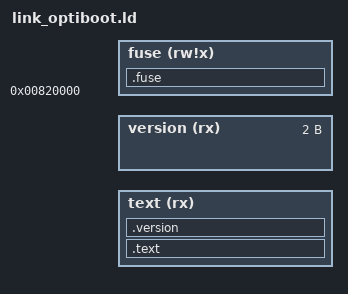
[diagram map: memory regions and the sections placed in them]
/* Customized Linker script for Optiboot */

/* Copyright (C) 2014-2015 Free Software Foundation, Inc.
   Copyright (C) 2021 by William Westfield
   Copying and distribution of this script, with or without modification,
   are permitted in any medium without royalty provided the copyright
   notice and this notice are preserved.
*/

/*
 * this is based off of the default ATmega328 linker script, but it
 * has been generalized (since optiboot makes little use of the standard
 * chip-specific values), and also specialized to based start addresses
 * of the code on symbols passed from the C program, instead of needing
 * --section-start commands in the linker command line.
 * (The C program does this by using asm() statements to define absolute
 * symbols that the linker can see.
 * The .data and .bss segments are removed, since the bootloader must not
 * use them (and does its own memory management) (this has the added
 * "benefit" of spitting out error messages if the code DOES try to
 * use data or bss variables.
 */

OUTPUT_FORMAT("elf32-avr","elf32-avr","elf32-avr")
__FUSE_REGION_LENGTH__ = DEFINED(__FUSE_REGION_LENGTH__) ? __FUSE_REGION_LENGTH__ : 1K;
/* This makes the disassembly listings prettier */
__RAM__ = 0x800000;

MEMORY
{
  text   (rx)   : ORIGIN = __BOOT_START__, LENGTH = __BOOT_SIZE__
  version   (rx)   : ORIGIN = __VERSION_START__, LENGTH = 2
  fuse      (rw!x) : ORIGIN = 0x820000, LENGTH = __FUSE_REGION_LENGTH__
}

SECTIONS
{
  /* Read-only sections, merged into text segment: */
  /* Internal text space or external memory.  */
  .text   :
  {
    *(.vectors)
    KEEP(*(.vectors))
    /* For data that needs to reside in the lower 64k of progmem.  */
     *(.progmem.gcc*)
    /* PR 13812: Placing the trampolines here gives a better chance
       that they will be in range of the code that uses them.  */
    . = ALIGN(2);
    *(.init0)  /* Start here after reset.  */
    KEEP (*(.init0))
    *(.init1)
    KEEP (*(.init1))
    *(.init2)  /* Clear __zero_reg__, set up stack pointer.  */
    KEEP (*(.init2))
    *(.init3)
    KEEP (*(.init3))
    *(.init4)  /* Initialize data and BSS.  */
    KEEP (*(.init4))
    *(.init5)
    KEEP (*(.init5))
    *(.init6)  /* C++ constructors.  */
    KEEP (*(.init6))
    *(.init7)
    KEEP (*(.init7))
    *(.init8)
    KEEP (*(.init8))
    *(.init9)  /* Call main().  */
    KEEP (*(.init9))
    *(.text)
    . = ALIGN(2);
     *(.text.*)
    . = ALIGN(2);
    *(.fini9)  /* _exit() starts here.  */
    KEEP (*(.fini9))
    *(.fini8)
    KEEP (*(.fini8))
    *(.fini7)
    KEEP (*(.fini7))
    *(.fini6)  /* C++ destructors.  */
    KEEP (*(.fini6))
    *(.fini5)
    KEEP (*(.fini5))
    *(.fini4)
    KEEP (*(.fini4))
    *(.fini3)
    KEEP (*(.fini3))
    *(.fini2)
    KEEP (*(.fini2))
    *(.fini1)
    KEEP (*(.fini1))
    *(.fini0)  /* Infinite loop after program termination.  */
    KEEP (*(.fini0))
     _etext = . ;
  }  > text
  .version __VERSION_START__ :
  {
    *(.version)
  } > text
  .fuse  :
  {
    KEEP(*(.fuse))
    KEEP(*(.lfuse))
    KEEP(*(.hfuse))
    KEEP(*(.efuse))
  }  > fuse
  /* Stabs debugging sections.  */
  .stab 0 : { *(.stab) }
  .stabstr 0 : { *(.stabstr) }
  .stab.excl 0 : { *(.stab.excl) }
  .stab.exclstr 0 : { *(.stab.exclstr) }
  .stab.index 0 : { *(.stab.index) }
  .stab.indexstr 0 : { *(.stab.indexstr) }
  .comment 0 : { *(.comment) }
  .note.gnu.build-id : { *(.note.gnu.build-id) }
  /* DWARF debug sections.
     Symbols in the DWARF debugging sections are relative to the beginning
     of the section so we begin them at 0.  */
  /* DWARF 1 */
  .debug          0 : { *(.debug) }
  .line           0 : { *(.line) }
  /* GNU DWARF 1 extensions */
  .debug_srcinfo  0 : { *(.debug_srcinfo) }
  .debug_sfnames  0 : { *(.debug_sfnames) }
  /* DWARF 1.1 and DWARF 2 */
  .debug_aranges  0 : { *(.debug_aranges) }
  .debug_pubnames 0 : { *(.debug_pubnames) }
  /* DWARF 2 */
  .debug_info     0 : { *(.debug_info .gnu.linkonce.wi.*) }
  .debug_abbrev   0 : { *(.debug_abbrev) }
  .debug_line     0 : { *(.debug_line .debug_line.* .debug_line_end ) }
  .debug_frame    0 : { *(.debug_frame) }
  .debug_str      0 : { *(.debug_str) }
  .debug_loc      0 : { *(.debug_loc) }
  .debug_macinfo  0 : { *(.debug_macinfo) }
  /* SGI/MIPS DWARF 2 extensions */
  .debug_weaknames 0 : { *(.debug_weaknames) }
  .debug_funcnames 0 : { *(.debug_funcnames) }
  .debug_typenames 0 : { *(.debug_typenames) }
  .debug_varnames  0 : { *(.debug_varnames) }
  /* DWARF 3 */
  .debug_pubtypes 0 : { *(.debug_pubtypes) }
  .debug_ranges   0 : { *(.debug_ranges) }
  /* DWARF Extension.  */
  .debug_macro    0 : { *(.debug_macro) }
}
